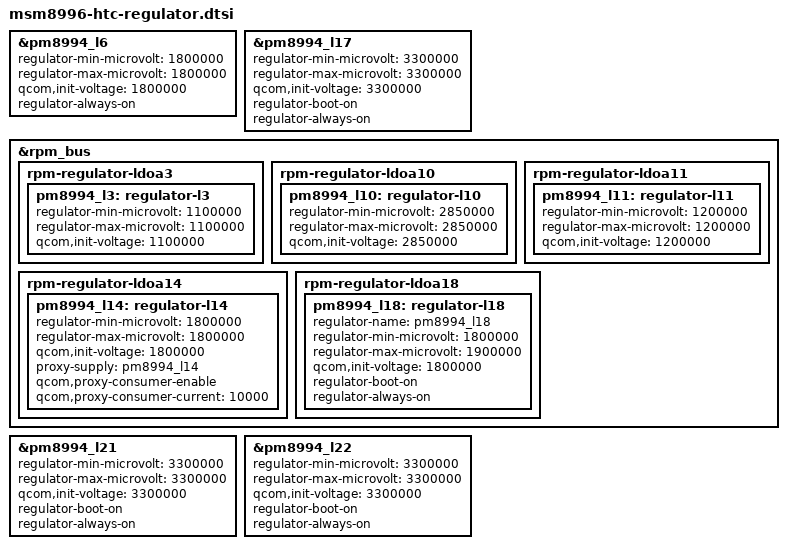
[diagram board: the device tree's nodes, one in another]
/* Copyright (c) 2016, The Linux Foundation. All rights reserved.
 *
 * This program is free software; you can redistribute it and/or modify
 * it under the terms of the GNU General Public License version 2 and
 * only version 2 as published by the Free Software Foundation.
 *
 * This program is distributed in the hope that it will be useful,
 * but WITHOUT ANY WARRANTY; without even the implied warranty of
 * MERCHANTABILITY or FITNESS FOR A PARTICULAR PURPOSE.  See the
 * GNU General Public License for more details.
 */

/*
 * msm8996-htc-regulator: common regulator config of HTC msm8996 projects
 */

&pm8994_l6 {
	regulator-min-microvolt = <1800000>;
	regulator-max-microvolt = <1800000>;
	qcom,init-voltage = <1800000>;
	regulator-always-on;
};

&pm8994_l17 {
	regulator-min-microvolt = <3300000>;
	regulator-max-microvolt = <3300000>;
	qcom,init-voltage = <3300000>;
	status = "okay";
	regulator-boot-on;
	regulator-always-on;
};

&rpm_bus {
	rpm-regulator-ldoa3 {
		status = "okay";
		pm8994_l3: regulator-l3 {
			regulator-min-microvolt = <1100000>;
			regulator-max-microvolt = <1100000>;
			qcom,init-voltage = <1100000>;
			status = "okay";
		};
	};
	rpm-regulator-ldoa10 {
		status = "okay";
		pm8994_l10: regulator-l10 {
			regulator-min-microvolt = <2850000>;
			regulator-max-microvolt = <2850000>;
			qcom,init-voltage = <2850000>;
			status = "okay";
		};
	};
	rpm-regulator-ldoa11 {
		status = "okay";
		pm8994_l11: regulator-l11 {
			regulator-min-microvolt = <1200000>;
			regulator-max-microvolt = <1200000>;
			qcom,init-voltage = <1200000>;
			status = "okay";
		};
	};
	rpm-regulator-ldoa14 {
		status = "okay";
		pm8994_l14: regulator-l14 {
			regulator-min-microvolt = <1800000>;
			regulator-max-microvolt = <1800000>;
			qcom,init-voltage = <1800000>;
			proxy-supply = <&pm8994_l14>;
			qcom,proxy-consumer-enable;
			qcom,proxy-consumer-current = <10000>;
			status = "okay";
		};
	};
	rpm-regulator-ldoa18 {
		pm8994_l18: regulator-l18 {
			regulator-name = "pm8994_l18";
			regulator-min-microvolt = <1800000>;
			regulator-max-microvolt = <1900000>;
			qcom,init-voltage = <1800000>;
			status = "okay";
			regulator-boot-on;
			regulator-always-on;

			/delete-property/ qcom,enable-with-pin-ctrl;
		};
	};
};

&pm8994_l21 {
	regulator-min-microvolt = <3300000>;
	regulator-max-microvolt = <3300000>;
	qcom,init-voltage = <3300000>;
	status = "okay";
	regulator-boot-on;
	regulator-always-on;
};

&pm8994_l22 {
	regulator-min-microvolt = <3300000>;
	regulator-max-microvolt = <3300000>;
	qcom,init-voltage = <3300000>;
	status = "okay";
	regulator-boot-on;
	regulator-always-on;
};
